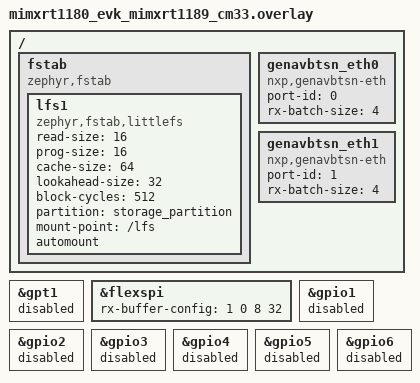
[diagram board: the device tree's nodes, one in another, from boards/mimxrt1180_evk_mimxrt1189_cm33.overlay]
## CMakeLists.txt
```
# SPDX-License-Identifier: BSD-3-Clause

cmake_minimum_required(VERSION 3.20.0)

# Use NEWLIB as libc to make it work with ARM GNU Toolchain out of the box.
set(TOOLCHAIN_HAS_NEWLIB ON)

# Common configuration fragment files
list(APPEND EXTRA_CONF_FILE
  "../../common/configs/base.conf"
  "../../common/configs/runtime-stats.conf"
)

# Common device tree overlays
if("${BOARD}" STREQUAL "mimxrt1180_evk/mimxrt1189/cm33")
  list(APPEND EXTRA_DTC_OVERLAY_FILE
    "../../common/overlays/mimxrt1180_evk_mimxrt1189_cm33_ocram1_ram.overlay"
  )
endif()

find_package(Zephyr REQUIRED HINTS $ENV{ZEPHYR_BASE})
project(tsn_init)
set(MCUX_SDK_PROJECT_NAME app)

SET(HAL_NXP_PATH "${ZEPHYR_BASE}/../modules/hal/nxp")
SET(SdkRootDirPath "${HAL_NXP_PATH}/mcux/mcux-sdk-ng")

include(../../common/libs/sys_heap_stats/sys_heap_stats.cmake)

function(include_mcux_driver driver)
  set(CONFIG_MCUX_COMPONENT_driver.${driver} ON)
  include(${SdkRootDirPath}/drivers/${driver}/CMakeLists.txt)
endfunction()

if(CONFIG_BOARD_MIMXRT1180_EVK_MIMXRT1189_CM33)
  include_mcux_driver(rgpio)
  include_mcux_driver(gpt)
  set(CONFIG_MCUX_COMPONENT_driver.netc_rt1180 ON)
  set(CONFIG_MCUX_COMPONENT_driver.netc_switch ON)
  include_mcux_driver(netc)
  include_mcux_driver(msgintr)

  set(CONFIG_MCUX_COMPONENT_component.eth_phy_common ON)
  set(CONFIG_MCUX_COMPONENT_component.phyrtl8201 ON)
  set(CONFIG_MCUX_COMPONENT_component.phyrtl8211f ON)
  include(${SdkRootDirPath}/components/phy/CMakeLists.txt)

  set(BoardDir "evkmimxrt1180/cm33")
endif()

include(genavb_sdk.cmake)

if(CONFIG_CODE_DATA_RELOCATION)
  set(TCM_FILES "")

  if(CONFIG_CPU_CORTEX_M_HAS_VTOR)
    list(APPEND TCM_FILES
      ${ZEPHYR_BASE}/arch/arm/core/cortex_m/isr_wrapper.c
      ${ZEPHYR_BASE}/arch/arm/core/cortex_m/exc_exit.c
    )
  endif()

  list(APPEND TCM_FILES
    ${ZEPHYR_BASE}/kernel/timer.c
    ${ZEPHYR_BASE}/kernel/timeout.c
    ${ZEPHYR_BASE}/kernel/sched.c
    ${ZEPHYR_BASE}/kernel/msg_q.c
    ${ZEPHYR_BASE}/kernel/mutex.c
    ${ZEPHYR_BASE}/kernel/idle.c
    ${ZEPHYR_BASE}/kernel/kheap.c
    ${ZEPHYR_BASE}/kernel/sem.c
    ${ZEPHYR_BASE}/kernel/spinlock_validate.c
    ${ZEPHYR_BASE}/kernel/thread.c
    ${ZEPHYR_BASE}/kernel/timeslicing.c
    ${ZEPHYR_BASE}/kernel/thread.c
    ${ZEPHYR_BASE}/kernel/thread_monitor.c
    ${ZEPHYR_BASE}/kernel/device.c
    ${ZEPHYR_BASE}/kernel/cpu_mask.c
    ${ZEPHYR_BASE}/kernel/dynamic.c
    ${ZEPHYR_BASE}/kernel/events.c
    ${ZEPHYR_BASE}/arch/arm/core/cortex_m/thread.c
    ${ZEPHYR_BASE}/arch/arm/core/cortex_m/swap_helper.S
    ${ZEPHYR_BASE}/arch/arm/core/cortex_m/irq_manage.c
    ${ZEPHYR_BASE}/arch/common/sw_isr_common.c
  )

  zephyr_code_relocate(FILES ${TCM_FILES} LOCATION ITCM_TEXT_RODATA NOKEEP)
  zephyr_code_relocate(FILES ${TCM_FILES} LOCATION DTCM_DATA_BSS_NOINIT NOKEEP)

  # mempool.c have the system heap in the data section:
  # Do not relocate the NOINIT section to DTCM and overuse it just for the system heap
  zephyr_code_relocate(FILES ${ZEPHYR_BASE}/kernel/mempool.c LOCATION ITCM_TEXT_RODATA NOKEEP)
  zephyr_code_relocate(FILES ${ZEPHYR_BASE}/kernel/mempool.c LOCATION DTCM_DATA_BSS NOKEEP)

endif()

zephyr_compile_definitions_ifdef(CONFIG_BOARD_MIMXRT1180_EVK_MIMXRT1189_CM33 CONFIG_APP_TSN_BRIDGE)
zephyr_compile_definitions_ifdef(CONFIG_BOARD_MIMXRT1180_EVK_MIMXRT1189_CM33 CONFIG_APP_EP_NUM_PORTS=2)
zephyr_compile_definitions_ifdef(CONFIG_BOARD_MIMXRT1180_EVK_MIMXRT1189_CM33 CONFIG_APP_EP_LOGICAL_PORT_LIST={0,1})

set(RTOS_ABSTRACTION_LAYER_TARGET ${MCUX_SDK_PROJECT_NAME})
include(${RTOS_ABSTRACTION_LAYER_DIR}/rtos_abstraction_layer.cmake)

target_sources(app PRIVATE
  src/boards/${BoardDir}/board.c
  src/boards/${BoardDir}/clock_config.c
  src/boards/${BoardDir}/pin_mux.c
  src/common/configs.c
  src/common/gavb_stack.c
  src/common/system_config.c
  src/main.c
)

zephyr_include_directories(
  src/common
  src/boards/${BoardDir}
)
```

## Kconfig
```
# Copyright 2026 NXP
# SPDX-License-Identifier: BSD-3-Clause

source "Kconfig.zephyr"

rsource "../../common/libs/sys_heap_stats/Kconfig"

rsource "../../common/configs/Kconfig.tsn_apps"

rsource "Kconfig.multicore"

config APP_STORAGE
    bool "Enable storage support"
    default y

choice APP_TSN_BUILD_PROFILE
    prompt "TSN build profile options"
    default APP_TSN_BUILD_PROFILE_DEFAULT

    config APP_TSN_BUILD_PROFILE_DEFAULT
        bool "TSN Bridge default profile"
        select APP_TSN_BRIDGE
        select APP_QBV
        select APP_FP

endchoice
```

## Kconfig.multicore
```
config TSN_MULTICORE
        bool "TSN Multicore"
        depends on SECOND_CORE_MCUX
        default n

config TSN_MULTICORE_PRIMARY
        bool "TSN Multicore Primary"
        depends on TSN_MULTICORE
        default y if TSN_MULTICORE && BOARD_MIMXRT1180_EVK_MIMXRT1189_CM33

config TSN_MULTICORE_SECONDARY
        bool "TSN Multicore Secondary"
        depends on TSN_MULTICORE
        default y if TSN_MULTICORE && BOARD_MIMXRT1180_EVK_MIMXRT1189_CM7
```

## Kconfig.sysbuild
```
source "share/sysbuild/Kconfig"

config SECONDARY_BOARD
        string "Remote board"
        default "mimxrt1180_evk/mimxrt1189/cm7" if $(BOARD) = "mimxrt1180_evk"

config TSN_MULTICORE_BUILD
        bool "Build TSN multicore images"
        default y
```

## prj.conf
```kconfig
# Copyright 2026 NXP
# SPDX-License-Identifier: BSD-3-Clause

CONFIG_EVENTS=y
CONFIG_DYNAMIC_INTERRUPTS=y

# RTOS Abstraction Layer dependencies
CONFIG_DYNAMIC_THREAD=y
CONFIG_DYNAMIC_THREAD_ALLOC=y

CONFIG_NOCACHE_MEMORY=y

CONFIG_NET_IF_MAX_IPV4_COUNT=2
```

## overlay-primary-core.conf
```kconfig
CONFIG_TSN_MULTICORE=y
CONFIG_MBOX=y
CONFIG_SECOND_CORE_MCUX=y
CONFIG_CM7_BOOT_FROM_FLASH=y
```

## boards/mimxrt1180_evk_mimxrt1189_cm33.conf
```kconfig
CONFIG_LOG_BUFFER_SIZE=32768
CONFIG_HEAP_MEM_POOL_SIZE=102400

CONFIG_CODE_DATA_RELOCATION=y
```

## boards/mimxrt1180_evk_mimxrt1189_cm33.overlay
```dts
/*
 * Copyright 2026 NXP
 *
 * SPDX-License-Identifier: BSD-3-Clause
 */

/ {
	fstab {
		compatible = "zephyr,fstab";
		lfs1: lfs1 {
			compatible = "zephyr,fstab,littlefs";
			read-size = <16>;
			prog-size = <16>;
			cache-size = <64>;
			lookahead-size = <32>;
			block-cycles = <512>;
			partition = <&storage_partition>;
			mount-point = "/lfs";
			automount;
		};
	};
};

/* Disable peripherals handled outside the Zephyr device model */
/delete-node/ &netc;

&gpt1 {
	status = "disabled";
};

&flexspi {
	/* AHB RX buffer: <prefetch priority master_id buf_size> */
	rx-buffer-config = <1 0 8 32>;
};

/* Disable all gpio nodes: the stack uses its own RGPIO driver when needed. */
&gpio1 {
	status = "disabled";
};

&gpio2 {
	status = "disabled";
};

&gpio3 {
	status = "disabled";
};

&gpio4 {
	status = "disabled";
};

&gpio5 {
	status = "disabled";
};

&gpio6 {
	status = "disabled";
};

/ {
	genavbtsn_eth0: genavbtsn_eth0 {
		compatible = "nxp,genavbtsn-eth";
		port-id = <0>;
		rx-batch-size = <4>;
		status = "okay";
	};

	genavbtsn_eth1: genavbtsn_eth1 {
		compatible = "nxp,genavbtsn-eth";
		port-id = <1>;
		rx-batch-size = <4>;
		status = "okay";
	};
};
```

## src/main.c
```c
/*
 * Copyright 2026 NXP
 *
 * SPDX-License-Identifier: BSD-3-Clause
 */

#include <stdio.h>

#include <zephyr/kernel.h>

#include "gavb_stack.h"
#include "board.h"

#include <zephyr/shell/shell.h>
#include "genavb_shell.h"

#define TSN_INIT_STACK_SIZE 4096
#define TSN_INIT_STACK_PRIO (K_LOWEST_THREAD_PRIO - 4)

K_THREAD_STACK_DEFINE(tsn_init_stack, TSN_INIT_STACK_SIZE);
struct k_thread tsn_init_thread;

static void tsn_init_main(void *p1, void *p2, void *p3)
{
    int rc;

    printk("Starting GenAVB/TSN stack: enter\n");

    rc = gavb_stack_init();
    if (rc < 0)
        goto exit;

    genavb_shell_init();

    printk("Starting GenAVB/TSN stack: success\n");
    return;

exit:
    printk("Starting GenAVB/TSN stack: failed\n");
}

int main(void)
{
    k_tid_t thread_ret;

    BOARD_Init();
    BOARD_InitNVIC();

    printk("Main: started\n");

    thread_ret = k_thread_create(&tsn_init_thread, tsn_init_stack, TSN_INIT_STACK_SIZE,
                &tsn_init_main, NULL, NULL, NULL,
                TSN_INIT_STACK_PRIO, 0, K_NO_WAIT);

    return 0;
}
```

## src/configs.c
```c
/*
 * Copyright 2022, 2024-2026 NXP
 *
 * SPDX-License-Identifier: BSD-3-Clause
 */

#include "gavb_stack.h"
#include "system_config.h"
#include "shared_config.h"

#define MAC_ADDR_BYTE_1 0xEE

struct net_config system_net_cfg[CONFIG_APP_LOGICAL_PORTS] = {
    [0] = {
        .hw_addr = {0x00, 0xBB, 0xCC, 0xDD, MAC_ADDR_BYTE_1, 0x00},
        .ip_addr = {192, 168, 1, 4},
        .net_mask = {255, 255, 255, 0},
        .gw_addr = {192, 168, 1, 254},
    },
#if CONFIG_APP_LOGICAL_PORTS > 1
    [1] = {
        .hw_addr = {0x00, 0xBB, 0xCC, 0xDD, MAC_ADDR_BYTE_1, 0x01},
        .ip_addr = {192, 168, 2, 4},
        .net_mask = {255, 255, 255, 0},
        .gw_addr = {192, 168, 2, 254},
    },
#endif
#if CONFIG_APP_LOGICAL_PORTS > 2
    [2] = {
        .hw_addr = {0x00, 0x11, 0x22, 0x33, 0x44, 0x02},
    },
#endif
#if CONFIG_APP_LOGICAL_PORTS > 3
    [3] = {
        .hw_addr = {0x00, 0x11, 0x22, 0x33, 0x44, 0x03},
    },
#endif
#if CONFIG_APP_LOGICAL_PORTS > 4
    [4] = {
        .hw_addr = {0x00, 0x11, 0x22, 0x33, 0x44, 0x04},
     },
#endif
#if CONFIG_APP_LOGICAL_PORTS > 5
    [5] = {
        .hw_addr = {0x00, 0x11, 0x22, 0x33, 0x44, 0x05},
	},
#endif
#if CONFIG_APP_LOGICAL_PORTS > 6
    [6] = {
        .hw_addr = {0x00, 0x11, 0x22, 0x33, 0x44, 0x06},
    },
#endif
};

#if defined(CONFIG_TSN_MULTICORE)

#ifndef CONFIG_APP_CONTROLLER_NUM_IO_DEVICES
#define CONFIG_APP_CONTROLLER_NUM_IO_DEVICES 2
#endif

/* Default values for M7 configuration */
struct system_config_m7 m7_system_cfg = {
    .net = {
         [0] = {
             .hw_addr = {0x00, 0xBB, 0xCC, 0xDD, 0xEF, 0x10},
         },
#if CONFIG_APP_LOGICAL_PORTS_M7 > 1
         [1] = {
             .hw_addr = {0x00, 0xBB, 0xCC, 0xDD, 0xEF, 0x11},
         },
#endif
    },
};
#endif /* CONFIG_TSN_MULTICORE */
```
